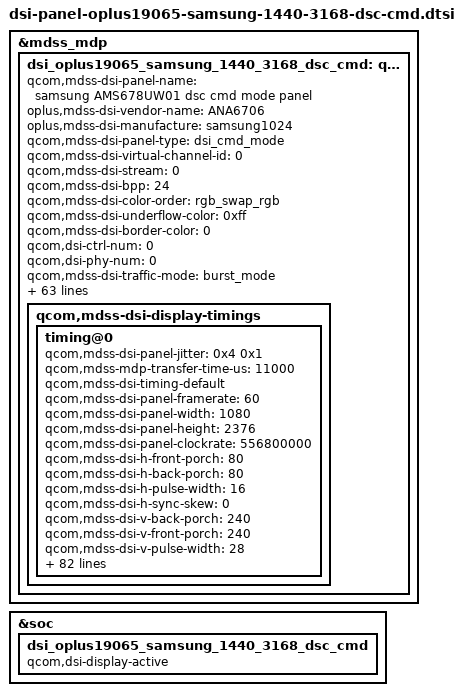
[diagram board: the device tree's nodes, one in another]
&mdss_mdp {
	dsi_oplus19065_samsung_1440_3168_dsc_cmd: qcom,mdss_dsi_oplus19065_samsung_1440_3168_dsc_cmd {
		qcom,mdss-dsi-panel-name = "samsung AMS678UW01 dsc cmd mode panel";
		oplus,mdss-dsi-vendor-name = "ANA6706";
		oplus,mdss-dsi-manufacture = "samsung1024";
		qcom,mdss-dsi-panel-type = "dsi_cmd_mode";
		qcom,mdss-dsi-virtual-channel-id = <0>;
		qcom,mdss-dsi-stream = <0>;
		qcom,mdss-dsi-bpp = <24>;
		qcom,mdss-dsi-color-order = "rgb_swap_rgb";
		qcom,mdss-dsi-underflow-color = <0xff>;
		qcom,mdss-dsi-border-color = <0>;
		qcom,dsi-ctrl-num = <0>;
		qcom,dsi-phy-num = <0>;
		qcom,mdss-dsi-traffic-mode = "burst_mode";
		qcom,mdss-dsi-lane-map = "lane_map_0123";
		qcom,mdss-dsi-bllp-eof-power-mode;
		qcom,mdss-dsi-bllp-power-mode;
		qcom,mdss-dsi-lane-0-state;
		qcom,mdss-dsi-lane-1-state;
		qcom,mdss-dsi-lane-2-state;
		qcom,mdss-dsi-lane-3-state;
		qcom,mdss-dsi-dma-trigger = "trigger_sw";
		qcom,mdss-loading-effect;
		qcom,mdss-dsi-mdp-trigger = "none";
		qcom,mdss-dsi-reset-sequence = <1 10>, <0 1>, <1 10>;
		qcom,mdss-dsi-te-pin-select = <1>;
		qcom,mdss-dsi-te-dcs-command = <1>;
		qcom,mdss-brightness-max-level = <1023>;
		qcom,mdss-pan-physical-width-dimension = <71>;
		qcom,mdss-pan-physical-height-dimension = <154>;
		qcom,mdss-dsi-init-delay-us = <1000>;
		qcom,mdss-dsi-te-check-enable;
		qcom,mdss-dsi-te-using-te-pin;
		qcom,mdss-dsi-lp11-init;
		qcom,mdss-dsi-wr-mem-start = <0x2c>;
		qcom,mdss-dsi-wr-mem-continue = <0x3c>;
		qcom,mdss-dsi-panel-jitter = <0x4 0x1>;
		qcom,mdss-bl-high2bit;
		/* HDR Setting */
		qcom,mdss-dsi-panel-hdr-enabled;
		qcom,mdss-dsi-panel-hdr-color-primaries = <15635 16450 34000 16000 13250 34500 7500 3000>;
		qcom,mdss-dsi-panel-peak-brightness = <5400000>;
		qcom,mdss-dsi-panel-average-brightness = <2000000>;
		qcom,mdss-dsi-panel-blackness-level = <2000>;
		qcom,mdss-dsi-panel-seria-num-year-index = <11>;
		qcom,mdss-dsi-panel-seria-num-mon-index = <11>;
		qcom,mdss-dsi-panel-seria-num-day-index = <12>;
		qcom,mdss-dsi-panel-seria-num-hour-index = <13>;
		qcom,mdss-dsi-panel-seria-num-min-index = <14>;
		qcom,mdss-dsi-panel-seria-num-sec-index = <15>;
		qcom,mdss-dsi-panel-seria-num-msec-high-index = <16>;
		qcom,mdss-dsi-panel-seria-num-msec-low-index = <17>;
		//qcom,esd-check-enabled;
		//qcom,mdss-dsi-panel-status-check-mode = "reg_read";
		qcom,mdss-dsi-panel-status-command = [06 01 00 01 05 00 02 0A 00];
		qcom,mdss-dsi-panel-status-command-state = "dsi_lp_mode";
		qcom,mdss-dsi-panel-status-value = <0x9F>;
		qcom,mdss-dsi-panel-status-read-length = <1>;
		//qcom,dynamic-mode-switch-enabled;
		//qcom,dynamic-mode-switch-type = "dynamic-resolution-switch-immediate";
		qcom,mdss-dsi-display-timings {
			timing@0{
				qcom,mdss-dsi-panel-jitter = <0x4 0x1>;
				qcom,mdss-mdp-transfer-time-us = <11000>;
				qcom,mdss-dsi-timing-default;
				qcom,mdss-dsi-panel-framerate = <60>;
				qcom,mdss-dsi-panel-width = <1080>;
				qcom,mdss-dsi-panel-height = <2376>;
				qcom,mdss-dsi-panel-clockrate = <556800000>;
				qcom,mdss-dsi-h-front-porch = <80>;
				qcom,mdss-dsi-h-back-porch = <80>;
				qcom,mdss-dsi-h-pulse-width = <16>;
				qcom,mdss-dsi-h-sync-skew = <0>;
				qcom,mdss-dsi-v-back-porch = <240>;
				qcom,mdss-dsi-v-front-porch = <240>;
				qcom,mdss-dsi-v-pulse-width = <28>;
				qcom,mdss-dsi-h-sync-pulse = <0>;
				qcom,mdss-dsi-h-left-border = <0>;
				qcom,mdss-dsi-h-right-border = <0>;
				qcom,mdss-dsi-v-top-border = <0>;
				qcom,mdss-dsi-v-bottom-border = <0>;
				oplus,fod-on-vblank = <1>;
				oplus,fod-off-vblank = <0>;
				qcom,mdss-dsi-panel-read-register-open-command = [
					39 01 00 00 00 00 03 F0 5A 5A
					];
				qcom,mdss-dsi-panel-id1-command = [
					06 01 00 00 00 00 01 E9
					];
				qcom,mdss-dsi-panel-read-register-close-command = [
					39 01 00 00 00 00 03 F0 A5 A5
					];
				//qcom,mdss-dsi-timing-switch-command = [
				//	39 01 00 00 00 00 03 F0 5A 5A
				//	07 01 00 00 00 00 01 01
				//	15 01 00 00 00 00 02 60 02					/* 60HZ */
				//	15 01 00 00 00 00 02 BA 02
				//	15 01 00 00 00 00 02 F7 0F
				//	39 01 00 00 00 00 05 2A 00 00 04 37			/* CASET */
				//	39 01 00 00 00 00 05 2B 00 00 09 47			/* PASET */
				//	39 01 00 00 06 00 03 F0 A5 A5
				//];
				qcom,mdss-dsi-on-command = [
					/* Sleep Out(11h) */
					05 01 00 00 0B 00 01 11
					/* ELVDD/ELVSS soft-start Setting */
					39 01 00 00 00 00 03 F0 5A 5A
					15 01 00 00 00 00 02 B0 09
					15 01 00 00 00 00 02 B5 08
					39 01 00 00 00 00 03 F0 A5 A5
					39 01 00 00 00 00 03 F0 5A 5A
					15 01 00 00 00 00 02 B0 22
					15 01 00 00 00 00 02 F5 65
					15 01 00 00 00 00 02 B0 38
					15 01 00 00 00 00 02 F5 0F
					15 01 00 00 00 00 02 B0 56
					15 01 00 00 00 00 02 F5 C4
					39 01 00 00 00 00 03 F0 A5 A5
					39 01 00 00 00 00 03 F0 5A 5A
					15 01 00 00 00 00 02 B0 03
					39 01 00 00 00 00 03 CB FF FF
					15 01 00 00 00 00 02 F7 0F
					39 01 00 00 0B 00 03 F0 A5 A5
					/* PPS Setting */
					39 01 00 00 00 00 03 F0 5A 5A
					07 01 00 00 00 00 01 01						/* DSC enable */
					15 01 00 00 00 00 02 BA 02
					39 01 00 00 00 00 59 9E
					11 00 00 89 30 80 09 48
					04 38 00 48 02 1C 02 1C
					02 00 02 52 00 20 06 3B
					00 07 00 0F 01 B1 01 6A
					18 00 10 F0 03 0C 20 00
					06 0B 0B 33 0E 1C 2A 38
					46 54 62 69 70 77 79 7B
					7D 7E 01 02 01 00 09 40
					09 BE 19 FC 19 FA 19 F8
					1A 38 1A 78 1A B6 2A B6
					2A F4 2A F4 4B 34 63 74
					15 01 00 00 00 00 02 F7 0F
					39 01 00 00 00 00 03 F0 A5 A5
					/* Common Setting */
					15 01 00 00 00 00 02 35 00					/* TE On(Vsync) */
					/* CASET/PASET Setting */
					39 01 00 00 00 00 05 2A 00 00 04 37			/* CASET */
					39 01 00 00 00 00 05 2B 00 00 09 47			/* PASET */
					/* TSP SYNC Setting */
					39 01 00 00 00 00 03 F0 5A 5A
					15 01 00 00 00 00 02 B0 05
					39 01 00 00 00 00 05 B9 07 02 40 23			/* SYNC ENABLE */
					39 01 00 00 00 00 03 F0 A5 A5
					/* FREQ_MODE Setting */
					39 01 00 00 00 00 03 F0 5A 5A
					15 01 00 00 00 00 02 B0 0A
					15 01 00 00 00 00 02 FB 00
					39 01 00 00 00 00 03 F0 A5 A5
					/* FD(Fast Discharge) Setting */
					39 01 00 00 00 00 03 F0 5A 5A
					15 01 00 00 00 00 02 B0 54
					15 01 00 00 00 00 02 B5 48					/* mode ON */
					39 01 00 00 00 00 03 F0 A5 A5
					/* Dither Setting */
					39 01 00 00 00 00 03 F0 5A 5A
					15 01 00 00 00 00 02 99 40
					39 01 00 00 6F 00 03 F0 A5 A5
					/* Brightness Control */
					39 01 00 00 00 00 03 F0 5A 5A				/* Dimming Setting */
					15 01 00 00 00 00 02 B0 0B
					15 01 00 00 00 00 02 B1 01					/* Dimming Speed Setting : 0x01 : 1Frame*/
					15 01 00 00 00 00 02 B0 02
					15 01 00 00 00 00 02 B5 13					/* ELVSS DIM OFF */
					15 01 00 00 00 00 02 53 28
					39 01 00 00 00 00 03 F0 A5 A5
					/* 60hz ? 120hz Transition */
					39 01 00 00 00 00 03 F0 5A 5A
					15 01 00 00 00 00 02 60 02					/* 60HZ */
					15 01 00 00 00 00 02 F7 0F
					39 01 00 00 00 00 03 F0 A5 A5
					/* Display On */
					//05 01 00 00 00 00 01 29
				];
				qcom,mdss-dsi-post-on-backlight = [
					/* Display On */
					39 01 00 00 00 00 03 9F 5A 5A
					05 01 00 00 00 00 01 29
					05 01 00 00 00 00 01 13
					39 01 00 00 00 00 03 9F A5 A5
				];
				qcom,mdss-dsi-off-command=[
					05 01 00 00 0A 00 02 28 00
					05 01 00 00 78 00 02 10 00
				];
				qcom,mdss-dsi-lp1-command = [
					/* SEED CRC OFF */
					15 01 00 00 00 00 02 82 00
					/* Aod Mode */
					39 01 00 00 00 00 03 F0 5A 5A
					15 01 00 00 00 00 02 B0 06
					15 01 00 00 00 00 02 F4 8A
					15 01 00 00 00 00 02 BB 29
					15 01 00 00 00 00 02 6A 00
					15 01 00 00 00 00 02 53 22
					39 01 00 00 14 00 03 F0 A5 A5
				];
				qcom,mdss-dsi-nolp-command = [
					39 01 00 00 00 00 03 F0 5A 5A
					15 00 00 00 00 00 02 60 00 /*60HZ*/
					15 00 00 00 00 00 02 F7 0F
					39 01 00 00 00 00 03 F0 A5 A5
					/* Normal Mode */
					39 01 00 00 00 00 03 F0 5A 5A
					15 01 00 00 00 00 02 6A 00
					15 01 00 00 00 00 02 53 28
					39 01 00 00 00 00 03 F0 A5 A5
				];
				qcom,mdss-dsi-aod-hbm-on-command = [
					/* HBM Mode ON */
					39 01 00 00 00 00 02 53 E0
					/* 0xE0 Normal transition */
					39 01 00 00 00 00 03 51 05 93
				];
				qcom,mdss-dsi-aod-hbm-off-command = [
					15 01 00 00 00 00 02 53 22
					39 01 00 00 00 00 03 51 00 01
				];
				qcom,mdss-dsi-hbm-on-command = [
					15 01 00 00 00 00 02 53 E0
					39 01 00 00 22 00 03 51 05 93
				];
				qcom,mdss-dsi-normal-hbm-on-command = [
					15 01 00 00 00 00 02 53 E0
					39 01 00 00 00 00 03 51 07 FF
				];
				qcom,mdss-dsi-aod-high-mode-command = [
					/* AOD 50nit */
					15 01 00 00 00 00 02 53 22
				];
				qcom,mdss-dsi-aod-low-mode-command = [
					/* AOD 10nit */
					15 01 00 00 00 00 02 53 23
				];
				qcom,mdss-dsi-seed-off-command = [
					/* TCS OFF */
					39 01 00 00 00 00 03 F0 5A 5A
					15 01 00 00 00 00 02 84 00
					39 01 00 00 00 00 03 F0 A5 A5
					/* CRC OFF */
					39 01 00 00 00 00 03 F0 5A 5A
					15 01 00 00 00 00 02 B8 01
					39 01 00 00 00 00 03 F0 A5 A5
				];
				qcom,mdss-dsi-seed-0-command = [
					39 01 00 00 00 00 03 F0 5A 5A
					15 01 00 00 00 00 02 B0 0C
					15 01 00 00 00 00 02 92 07
					39 01 00 00 00 00 03 F0 A5 A5
					/* SEED CRC Setting*/
					15 01 00 00 00 00 02 82 82
					39 01 00 00 00 00 03 F0 5A 5A
					15 01 00 00 00 00 02 B0 2B  /* DCI-P3 */
					39 01 00 00 00 00 16 B8 FF 00 00 00 FF 00 00 00 FF 00 FF FF FF 00 FF FF FF 00 FF FF FF
					15 01 00 00 00 00 02 B8 00  /* CRC-ON */
					39 01 00 00 00 00 03 F0 A5 A5
				];
				qcom,mdss-dsi-seed-1-command = [
					39 01 00 00 00 00 03 F0 5A 5A
					15 01 00 00 00 00 02 B0 0C
					15 01 00 00 00 00 02 92 27
					39 01 00 00 00 00 03 F0 A5 A5
					/* SEED CRC Setting*/
					15 01 00 00 00 00 02 82 82
					39 01 00 00 00 00 03 F0 5A 5A
					15 01 00 00 00 00 02 B0 2B  /* DCI-P3 */
					39 01 00 00 00 00 16 B8 FF 00 00 00 FF 00 00 00 FF 00 FF FF FF 00 FF FF FF 00 FF FF FF
					15 01 00 00 00 00 02 B8 00  /* CRC-ON */
					39 01 00 00 00 00 03 F0 A5 A5
				];
				qcom,mdss-dsi-seed-2-command = [
					39 01 00 00 00 00 03 F0 5A 5A
					15 01 00 00 00 00 02 B0 0C
					15 01 00 00 00 00 02 92 07
					39 01 00 00 00 00 03 F0 A5 A5
					/* SEED CRC Setting*/
					15 01 00 00 00 00 02 82 82
					39 01 00 00 00 00 03 F0 5A 5A
					15 01 00 00 00 00 02 B0 2B  /* DCI-P3 */
					39 01 00 00 00 00 16 B8 FF 00 00 00 FF 00 00 00 FF 00 FF FF FF 00 FF FF FF 00 FF FF FF
					15 01 00 00 00 00 02 B8 00  /* CRC-ON */
					39 01 00 00 00 00 03 F0 A5 A5
				];
				qcom,mdss-dsi-mca-on-command = [
					/* MCA ON */
					39 01 00 00 00 00 03 F0 5A 5A
					15 01 00 00 00 00 02 B0 06
					15 01 00 00 00 00 02 97 01
					15 01 00 00 00 00 02 B0 04
					15 01 00 00 00 00 02 98 01
					39 01 00 00 00 00 03 F0 A5 A5
				];
				qcom,mdss-dsi-mca-off-command = [
					/* MCA OFF */
					39 01 00 00 00 00 03 F0 5A 5A
					15 01 00 00 00 00 02 B0 06
					15 01 00 00 00 00 02 97 00
					15 01 00 00 00 00 02 B0 04
					15 01 00 00 00 00 02 98 00
					39 01 00 00 00 00 03 F0 A5 A5
				];
				qcom,mdss-dsi-aod-hbm-on-command-state = "dsi_hs_mode";
				qcom,mdss-dsi-aod-hbm-off-command-state = "dsi_hs_mode";
				qcom,mdss-dsi-timing-switch-command-state = "dsi_hs_mode";
				qcom,mdss-dsi-on-command-state = "dsi_lp_mode";
				qcom,mdss-dsi-off-command-state = "dsi_hs_mode";
				qcom,mdss-dsi-seed-off-command-state = "dsi_hs_mode";
				qcom,mdss-dsi-seed-0-command-state = "dsi_hs_mode";
				qcom,mdss-dsi-seed-1-command-state = "dsi_hs_mode";
				qcom,mdss-dsi-seed-2-command-state = "dsi_hs_mode";

				qcom,compression-mode = "dsc";
				qcom,lm-split = <540 540>;
				qcom,mdss-dsc-encoders = <2>;
				qcom,mdss-dsc-slice-height = <72>;
				qcom,mdss-dsc-slice-width = <540>;
				qcom,mdss-dsc-slice-per-pkt = <2>;
				qcom,mdss-dsc-bit-per-component = <8>;
				qcom,mdss-dsc-bit-per-pixel = <8>;
				qcom,mdss-dsc-block-prediction-enable;
				qcom,mdss-dsi-panel-id1-command-state = "dsi_lp_mode";
				qcom,mdss-dsi-panel-read-register-open-state = "dsi_lp_mode";
				qcom,mdss-dsi-panel-read-register-close-state = "dsi_lp_mode";
			};
		};
	};
};

&soc {
	dsi_oplus19065_samsung_1440_3168_dsc_cmd {
		qcom,dsi-display-active;
	};
};

&dsi_oplus19065_samsung_1440_3168_dsc_cmd {
	qcom,panel-supply-entries = <&dsi_panel_pwr_supply>;
	//qcom,iris-supply-entries = <&dsi_iris_pwr_supply>;
	qcom,mdss-dsi-panel-controller = <&mdss_dsi0>;
	qcom,mdss-dsi-bl-pmic-control-type = "bl_ctrl_dcs";
	qcom,mdss-dsi-bl-min-level = <1>;
	qcom,mdss-dsi-bl-normal-max-level = <1023>;
	qcom,mdss-dsi-bl-max-level = <2047>;
	qcom,mdss-brightness-normal-max-level = <1023>;
	qcom,mdss-brightness-max-level = <2047>;
	qcom,mdss-brightness-default-level = <400>;
	qcom,platform-te-gpio = <&tlmm 82 0>;
	qcom,platform-reset-gpio = <&tlmm 24 0>;
	qcom,platform-panel-vout-gpio = <&tlmm 25 0>;
	qcom,ulps-enabled;
	qcom,dsi-select-clocks = "mux_byte_clk0", "mux_pixel_clk0";

	qcom,mdss-dsi-display-timings {
		timing@0 { /* FHD+ 60hz 278.4Mhz 556.8Mbps */
			qcom,mdss-dsi-panel-phy-timings = [00 14 05 05 1F 1F 05 05 03 02 04 00 12 15];
			qcom,display-topology = <1 1 1>,<2 2 1>;
			qcom,default-topology-index = <1>;
		};
		//timing@1 { /* FHD+ 120hz 412.8Mhz 825.6Mbps */
		//	qcom,mdss-dsi-panel-phy-timings = [00 1C 07 07 23 22 07 07 05 02 04 00 18 17];
		//	qcom,display-topology = <1 1 1>,<2 2 1>;
		//	qcom,default-topology-index = <1>;
		//};
		//timing@2 { /* WQHD+ 120hz 726Mhz 1452Mbps */
		//	qcom,mdss-dsi-panel-phy-timings = [00 2F 0C 0C 2A 27 0C 0D 09 02 04 00 26 1B];
		//	qcom,display-topology = <1 1 1>,<2 2 1>;
		//	qcom,default-topology-index = <1>;
		//};
		// timing@3 { /* WQHD+ 60hz 412.8Mhz 825.6Mbps */
		//	qcom,mdss-dsi-panel-phy-timings = [00 1C 07 07 23 22 07 07 05 02 04 00 18 17];
		//	qcom,display-topology = <1 1 1>,<2 2 1>;
		//	qcom,default-topology-index = <1>;
		//};
	};
};
